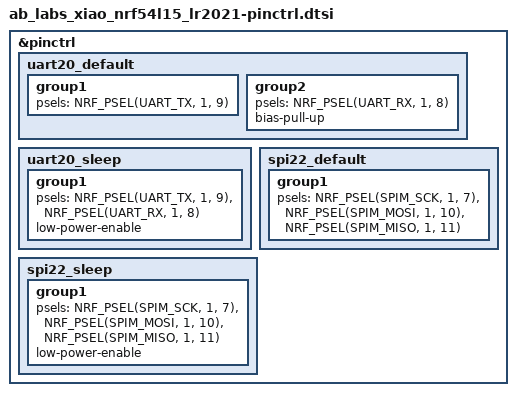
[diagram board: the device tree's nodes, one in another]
/*
 * AB Labs XIAO nRF54L15 + Wio-LR2021 carrier — pin control
 * Copyright (c) 2026 ZephCore
 * SPDX-License-Identifier: MIT
 *
 *   uart20  P1.09 TX / P1.08 RX                  — console, via the SAMD11 bridge
 *   spi22   P1.07 SCK / P1.10 MOSI / P1.11 MISO  — D3/D4/D5: LR2021
 *
 * The carrier wires the radio to D3/D4/D5, not to the XIAO's SPI pins
 * (D8..D10, spi00), so the bus is spi22 on port P1.
 */

&pinctrl {
	/omit-if-no-ref/ uart20_default: uart20_default {
		group1 {
			psels = <NRF_PSEL(UART_TX, 1, 9)>;
		};

		group2 {
			psels = <NRF_PSEL(UART_RX, 1, 8)>;
			bias-pull-up;
		};
	};

	/omit-if-no-ref/ uart20_sleep: uart20_sleep {
		group1 {
			psels = <NRF_PSEL(UART_TX, 1, 9)>,
				<NRF_PSEL(UART_RX, 1, 8)>;
			low-power-enable;
		};
	};

	/omit-if-no-ref/ spi22_default: spi22_default {
		group1 {
			psels = <NRF_PSEL(SPIM_SCK, 1, 7)>,
				<NRF_PSEL(SPIM_MOSI, 1, 10)>,
				<NRF_PSEL(SPIM_MISO, 1, 11)>;
		};
	};

	/omit-if-no-ref/ spi22_sleep: spi22_sleep {
		group1 {
			psels = <NRF_PSEL(SPIM_SCK, 1, 7)>,
				<NRF_PSEL(SPIM_MOSI, 1, 10)>,
				<NRF_PSEL(SPIM_MISO, 1, 11)>;
			low-power-enable;
		};
	};
};
